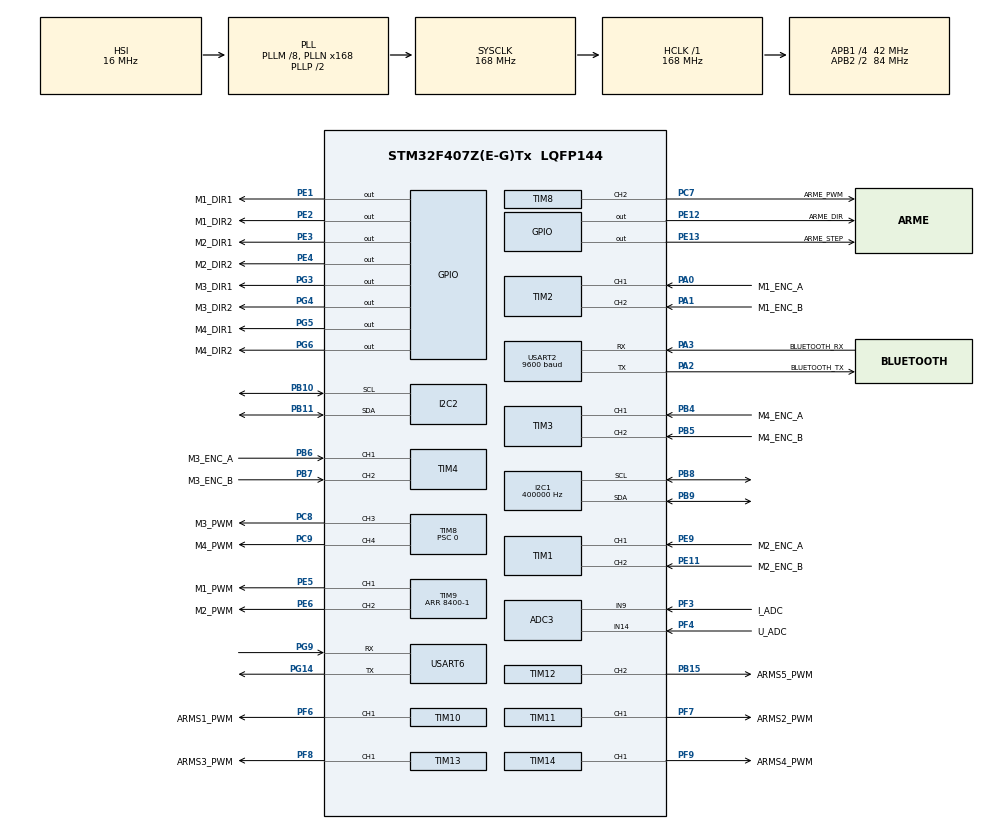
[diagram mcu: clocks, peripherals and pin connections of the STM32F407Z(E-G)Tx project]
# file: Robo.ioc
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ADC3.Channel-5\#ChannelRegularConversion=ADC_CHANNEL_9
ADC3.Channel-6\#ChannelRegularConversion=ADC_CHANNEL_14
ADC3.ClockPrescaler=ADC_CLOCK_SYNC_PCLK_DIV6
ADC3.ContinuousConvMode=ENABLE
ADC3.DMAContinuousRequests=ENABLE
ADC3.NbrOfConversion=2
ADC3.NbrOfConversionFlag=1
ADC3.Rank-5\#ChannelRegularConversion=1
ADC3.Rank-6\#ChannelRegularConversion=2
ADC3.SamplingTime-5\#ChannelRegularConversion=ADC_SAMPLETIME_144CYCLES
ADC3.SamplingTime-6\#ChannelRegularConversion=ADC_SAMPLETIME_144CYCLES
ADC3.ScanConvMode=ENABLE
Dma.ADC3.1.Direction=DMA_PERIPH_TO_MEMORY
Dma.ADC3.1.FIFOMode=DMA_FIFOMODE_DISABLE
Dma.ADC3.1.Instance=DMA2_Stream0
Dma.ADC3.1.MemDataAlignment=DMA_MDATAALIGN_HALFWORD
Dma.ADC3.1.MemInc=DMA_MINC_ENABLE
Dma.ADC3.1.Mode=DMA_CIRCULAR
Dma.ADC3.1.PeriphDataAlignment=DMA_PDATAALIGN_HALFWORD
Dma.ADC3.1.PeriphInc=DMA_PINC_DISABLE
Dma.ADC3.1.Priority=DMA_PRIORITY_HIGH
Dma.Request0=USART2_RX
Dma.Request1=ADC3
Dma.USART2_RX.0.Direction=DMA_PERIPH_TO_MEMORY
Dma.USART2_RX.0.FIFOMode=DMA_FIFOMODE_DISABLE
Dma.USART2_RX.0.Instance=DMA1_Stream5
Dma.USART2_RX.0.MemDataAlignment=DMA_MDATAALIGN_BYTE
Dma.USART2_RX.0.MemInc=DMA_MINC_ENABLE
Dma.USART2_RX.0.Mode=DMA_CIRCULAR
Dma.USART2_RX.0.PeriphDataAlignment=DMA_PDATAALIGN_BYTE
Dma.USART2_RX.0.PeriphInc=DMA_PINC_DISABLE
Dma.USART2_RX.0.Priority=DMA_PRIORITY_VERY_HIGH
FREERTOS.Queues01=remote_chassis,6,uint16_t,0,Static,remote_chassisBuffer,remote_chassisControlBlock
FREERTOS.Tasks01=ChassisTask,47,512,StartChassisTask,As weak,NULL,Dynamic,NULL,NULL;ActuatorTask,13,256,StartActuatorTask,As weak,NULL,Dynamic,NULL,NULL;SafetyTask,41,256,StartSafetyTask,As weak,NULL,Dynamic,NULL,NULL;SensorImuTask,38,512,StartSensorImuTask,As weak,NULL,Dynamic,NULL,NULL;OLEDPowerTask,35,768,StartOLEDPower,As weak,NULL,Dynamic,NULL,NULL;GrabTask,35,512,StartGrabTask,As weak,NULL,Dynamic,NULL,NULL;RemoteTask,32,512,StartRemoteTask,As weak,NULL,Dynamic,NULL,NULL
FREERTOS.configTOTAL_HEAP_SIZE=40960
I2C1.ClockSpeed=400000
I2C1.I2C_Mode=I2C_Fast
I2C2.I2C_Mode=I2C_Fast
IWDG.Prescaler=IWDG_PRESCALER_256
IWDG.Reload=500
Mcu.Family=STM32F4
Mcu.Name=STM32F407Z(E-G)Tx
Mcu.Package=LQFP144
NVIC.DMA1_Stream5_IRQn=true\:5\:0\:false\:false\:true\:true\:false\:true\:true
NVIC.DMA2_Stream0_IRQn=true\:5\:0\:false\:false\:true\:true\:false\:true\:true
NVIC.PriorityGroup=NVIC_PRIORITYGROUP_4
NVIC.TIM5_IRQn=true\:5\:0\:false\:false\:true\:true\:true\:true\:true
NVIC.TIM6_DAC_IRQn=true\:15\:0\:false\:false\:true\:false\:false\:true\:true
NVIC.TimeBase=TIM6_DAC_IRQn
NVIC.TimeBaseIP=TIM6
PA0-WKUP.GPIO_Label=M1_ENC_A
PA0-WKUP.Signal=S_TIM2_CH1_ETR
PA1.GPIO_Label=M1_ENC_B
PA1.Signal=S_TIM2_CH2
PA13.Mode=Serial_Wire
PA13.Signal=SYS_JTMS-SWDIO
PA14.Mode=Serial_Wire
PA14.Signal=SYS_JTCK-SWCLK
PA2.GPIO_Label=BLUETOOTH_TX
PA2.Mode=Asynchronous
PA2.Signal=USART2_TX
PA3.GPIO_Label=BLUETOOTH_RX
PA3.Mode=Asynchronous
PA3.Signal=USART2_RX
PB10.Mode=I2C
PB10.Signal=I2C2_SCL
PB11.Mode=I2C
PB11.Signal=I2C2_SDA
PB15.GPIO_Label=ARMS5_PWM
PB15.Signal=S_TIM12_CH2
PB4.GPIO_Label=M4_ENC_A
PB4.Signal=S_TIM3_CH1
PB5.GPIO_Label=M4_ENC_B
PB5.Signal=S_TIM3_CH2
PB6.GPIO_Label=M3_ENC_A
PB6.Signal=S_TIM4_CH1
PB7.GPIO_Label=M3_ENC_B
PB7.Signal=S_TIM4_CH2
PB8.Mode=I2C
PB8.Signal=I2C1_SCL
PB9.Mode=I2C
PB9.Signal=I2C1_SDA
PC7.GPIO_Label=ARME_PWM
PC7.Signal=S_TIM8_CH2
PC8.GPIO_Label=M3_PWM
PC8.Signal=S_TIM8_CH3
PC9.GPIO_Label=M4_PWM
PC9.Signal=S_TIM8_CH4
PE1.GPIO_Label=M1_DIR1
PE1.Signal=GPIO_Output
PE11.GPIO_Label=M2_ENC_B
PE11.Signal=S_TIM1_CH2
PE12.GPIO_Label=ARME_DIR
PE12.Signal=GPIO_Output
PE13.GPIO_Label=ARME_STEP
PE13.Signal=GPIO_Output
PE2.GPIO_Label=M1_DIR2
PE2.Signal=GPIO_Output
PE3.GPIO_Label=M2_DIR1
PE3.Signal=GPIO_Output
PE4.GPIO_Label=M2_DIR2
PE4.Signal=GPIO_Output
PE5.GPIO_Label=M1_PWM
PE5.Signal=S_TIM9_CH1
PE6.GPIO_Label=M2_PWM
PE6.Signal=S_TIM9_CH2
PE9.GPIO_Label=M2_ENC_A
PE9.Signal=S_TIM1_CH1
PF3.GPIO_Label=I_ADC
PF3.Mode=IN9
PF3.Signal=ADC3_IN9
PF4.GPIO_Label=U_ADC
PF4.Mode=IN14
PF4.Signal=ADC3_IN14
PF6.GPIO_Label=ARMS1_PWM
PF6.Signal=S_TIM10_CH1
PF7.GPIO_Label=ARMS2_PWM
PF7.Signal=S_TIM11_CH1
PF8.GPIO_Label=ARMS3_PWM
PF8.Signal=S_TIM13_CH1
PF9.GPIO_Label=ARMS4_PWM
PF9.Signal=S_TIM14_CH1
PG14.Mode=Asynchronous
PG14.Signal=USART6_TX
PG3.GPIO_Label=M3_DIR1
PG3.Signal=GPIO_Output
PG4.GPIO_Label=M3_DIR2
PG4.Signal=GPIO_Output
PG5.GPIO_Label=M4_DIR1
PG5.Signal=GPIO_Output
PG6.GPIO_Label=M4_DIR2
PG6.Signal=GPIO_Output
PG9.Mode=Asynchronous
PG9.Signal=USART6_RX
PH0-OSC_IN.Mode=HSE-External-Oscillator
PH0-OSC_IN.Signal=RCC_OSC_IN
PH1-OSC_OUT.Mode=HSE-External-Oscillator
PH1-OSC_OUT.Signal=RCC_OSC_OUT
ProjectManager.HeapSize=0x200
ProjectManager.StackSize=0x400
ProjectManager.TargetToolchain=CMake
RCC.48MHZClocksFreq_Value=84000000
RCC.AHBFreq_Value=168000000
RCC.APB1CLKDivider=RCC_HCLK_DIV4
RCC.APB1Freq_Value=42000000
RCC.APB1TimFreq_Value=84000000
RCC.APB2CLKDivider=RCC_HCLK_DIV2
RCC.APB2Freq_Value=84000000
RCC.APB2TimFreq_Value=168000000
RCC.CortexFreq_Value=168000000
RCC.HCLKFreq_Value=168000000
RCC.HSE_VALUE=25000000
RCC.HSI_VALUE=16000000
RCC.LSE_VALUE=32768
RCC.PLLM=8
RCC.PLLN=168
RCC.SYSCLKFreq_VALUE=168000000
RCC.SYSCLKSource=RCC_SYSCLKSOURCE_PLLCLK
RCC.VCOOutputFreq_Value=336000000
SH.S_TIM10_CH1.0=TIM10_CH1,PWM Generation1 CH1
SH.S_TIM11_CH1.0=TIM11_CH1,PWM Generation1 CH1
SH.S_TIM12_CH2.0=TIM12_CH2,PWM Generation2 CH2
SH.S_TIM13_CH1.0=TIM13_CH1,PWM Generation1 CH1
SH.S_TIM14_CH1.0=TIM14_CH1,PWM Generation1 CH1
SH.S_TIM1_CH1.0=TIM1_CH1,Encoder_Interface
SH.S_TIM1_CH2.0=TIM1_CH2,Encoder_Interface
SH.S_TIM2_CH1_ETR.0=TIM2_CH1,Encoder_Interface
SH.S_TIM2_CH2.0=TIM2_CH2,Encoder_Interface
SH.S_TIM3_CH1.0=TIM3_CH1,Encoder_Interface
SH.S_TIM3_CH2.0=TIM3_CH2,Encoder_Interface
SH.S_TIM4_CH1.0=TIM4_CH1,Encoder_Interface
SH.S_TIM4_CH2.0=TIM4_CH2,Encoder_Interface
SH.S_TIM8_CH2.0=TIM8_CH2,PWM Generation2 CH2
SH.S_TIM8_CH3.0=TIM8_CH3,PWM Generation3 CH3
SH.S_TIM8_CH4.0=TIM8_CH4,PWM Generation4 CH4
SH.S_TIM9_CH1.0=TIM9_CH1,PWM Generation1 CH1
SH.S_TIM9_CH2.0=TIM9_CH2,PWM Generation2 CH2
TIM1.EncoderMode=TIM_ENCODERMODE_TI12
TIM1.IC1Filter=8
TIM1.IC2Filter=8
TIM10.AutoReloadPreload=TIM_AUTORELOAD_PRELOAD_ENABLE
TIM10.Channel=TIM_CHANNEL_1
TIM10.Period=20000-1
TIM10.Prescaler=168-1
TIM11.AutoReloadPreload=TIM_AUTORELOAD_PRELOAD_ENABLE
TIM11.Channel=TIM_CHANNEL_1
TIM11.Period=20000-1
TIM11.Prescaler=168-1
TIM12.AutoReloadPreload=TIM_AUTORELOAD_PRELOAD_ENABLE
TIM12.Channel-PWM\ Generation2\ CH2=TIM_CHANNEL_2
TIM12.Period=20000-1
TIM12.Prescaler=84-1
TIM13.AutoReloadPreload=TIM_AUTORELOAD_PRELOAD_ENABLE
TIM13.Channel=TIM_CHANNEL_1
TIM13.Period=20000-1
TIM13.Prescaler=84-1
TIM14.AutoReloadPreload=TIM_AUTORELOAD_PRELOAD_ENABLE
TIM14.Channel=TIM_CHANNEL_1
TIM14.Period=20000-1
TIM14.Prescaler=84-1
TIM2.EncoderMode=TIM_ENCODERMODE_TI12
TIM2.IC1Filter=8
TIM2.IC2Filter=8
TIM3.EncoderMode=TIM_ENCODERMODE_TI12
TIM3.IC1Filter=8
TIM3.IC2Filter=8
TIM4.EncoderMode=TIM_ENCODERMODE_TI12
TIM4.IC1Filter=8
TIM4.IC2Filter=8
TIM5.AutoReloadPreload=TIM_AUTORELOAD_PRELOAD_ENABLE
TIM5.Period=1000-1
TIM5.Prescaler=84-1
TIM8.Channel-PWM\ Generation2\ CH2=TIM_CHANNEL_2
TIM8.Channel-PWM\ Generation3\ CH3=TIM_CHANNEL_3
TIM8.Channel-PWM\ Generation4\ CH4=TIM_CHANNEL_4
TIM8.Period=8400-1
TIM8.Prescaler=0
TIM9.Channel-PWM\ Generation1\ CH1=TIM_CHANNEL_1
TIM9.Channel-PWM\ Generation2\ CH2=TIM_CHANNEL_2
TIM9.Period=8400-1
USART2.BaudRate=9600
USART2.VirtualMode=VM_ASYNC
USART6.VirtualMode=VM_ASYNC
VP_FREERTOS_VS_CMSIS_V2.Mode=CMSIS_V2
VP_IWDG_VS_IWDG.Mode=IWDG_Activate
VP_SYS_VS_tim6.Mode=TIM6
VP_TIM10_VS_ClockSourceINT.Mode=Enable_Timer
VP_TIM11_VS_ClockSourceINT.Mode=Enable_Timer
VP_TIM13_VS_ClockSourceINT.Mode=Enable_Timer
VP_TIM14_VS_ClockSourceINT.Mode=Enable_Timer
VP_TIM5_VS_ClockSourceINT.Mode=Internal
board=custom

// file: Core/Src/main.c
/* USER CODE BEGIN Header */
/**
  ******************************************************************************
  * @file           : main.c
  * @brief          : Main program body
  ******************************************************************************
  * @attention
  *
  * Copyright (c) 2026 STMicroelectronics.
  * All rights reserved.
  *
  * This software is licensed under terms that can be found in the LICENSE file
  * in the root directory of this software component.
  * If no LICENSE file comes with this software, it is provided AS-IS.
  *
  ******************************************************************************
  */
/* USER CODE END Header */
#include "main.h"
#include "cmsis_os.h"
#include "adc.h"
#include "dma.h"
#include "i2c.h"
#include "iwdg.h"
#include "tim.h"
#include "usart.h"
#include "gpio.h"

/* USER CODE BEGIN Includes */
#include "app_types.h" /* App_Init() 与任务入口声明（user/app_types.h）*/
#include "stepper.h"
/* USER CODE END Includes */

void SystemClock_Config(void);
void MX_FREERTOS_Init(void);

int main(void)
{

  /* MCU Configuration--------------------------------------------------------*/

  /* Reset of all peripherals, Initializes the Flash interface and the Systick. */
  HAL_Init();

  /* Configure the system clock */
  SystemClock_Config();

  /* Initialize all configured peripherals */
  MX_GPIO_Init();
  MX_DMA_Init();
  MX_TIM2_Init();
  MX_TIM3_Init();
  MX_TIM4_Init();
  MX_TIM8_Init();
  MX_TIM12_Init();
  MX_ADC3_Init();
  MX_I2C2_Init();
  MX_TIM9_Init();
  MX_USART2_UART_Init();
  MX_USART6_UART_Init();
  MX_TIM10_Init();
  MX_TIM11_Init();
  MX_TIM13_Init();
  MX_TIM14_Init();
  MX_TIM1_Init();
  MX_I2C1_Init();
  MX_IWDG_Init();
  MX_TIM5_Init();
  /* USER CODE BEGIN 2 */

  /* 应用层初始化：建静态队列 + 建任务（全部 xTaskCreateStatic，不用 heap）。
   * 必须在 osKernelStart() 之前调用：任务创建本身不依赖调度器，
   * 但必须在调度器启动时就已经存在于就绪列表里。
   * 详见 user/remote.c 的 App_Init()。 */
  App_Init();

  /* USER CODE END 2 */

  /* Init scheduler */
  osKernelInitialize();  /* Call init function for freertos objects (in cmsis_os2.c) */
  MX_FREERTOS_Init();

  /* Start scheduler */
  osKernelStart();

  /* We should never get here as control is now taken by the scheduler */

  /* Infinite loop */
  while (1)
  {

  }
}

void SystemClock_Config(void)
{
  RCC_OscInitTypeDef RCC_OscInitStruct = {0};
  RCC_ClkInitTypeDef RCC_ClkInitStruct = {0};

  /** Configure the main internal regulator output voltage
  */
  __HAL_RCC_PWR_CLK_ENABLE();
  __HAL_PWR_VOLTAGESCALING_CONFIG(PWR_REGULATOR_VOLTAGE_SCALE1);

  /** Initializes the RCC Oscillators according to the specified parameters
  * in the RCC_OscInitTypeDef structure.
  */
  RCC_OscInitStruct.OscillatorType = RCC_OSCILLATORTYPE_HSI|RCC_OSCILLATORTYPE_LSI;
  RCC_OscInitStruct.HSIState = RCC_HSI_ON;
  RCC_OscInitStruct.HSICalibrationValue = RCC_HSICALIBRATION_DEFAULT;
  RCC_OscInitStruct.LSIState = RCC_LSI_ON;
  RCC_OscInitStruct.PLL.PLLState = RCC_PLL_ON;
  RCC_OscInitStruct.PLL.PLLSource = RCC_PLLSOURCE_HSI;
  RCC_OscInitStruct.PLL.PLLM = 8;
  RCC_OscInitStruct.PLL.PLLN = 168;
  RCC_OscInitStruct.PLL.PLLP = RCC_PLLP_DIV2;
  RCC_OscInitStruct.PLL.PLLQ = 4;
  if (HAL_RCC_OscConfig(&RCC_OscInitStruct) != HAL_OK)
  {
    Error_Handler();
  }

  /** Initializes the CPU, AHB and APB buses clocks
  */
  RCC_ClkInitStruct.ClockType = RCC_CLOCKTYPE_HCLK|RCC_CLOCKTYPE_SYSCLK
                              |RCC_CLOCKTYPE_PCLK1|RCC_CLOCKTYPE_PCLK2;
  RCC_ClkInitStruct.SYSCLKSource = RCC_SYSCLKSOURCE_PLLCLK;
  RCC_ClkInitStruct.AHBCLKDivider = RCC_SYSCLK_DIV1;
  RCC_ClkInitStruct.APB1CLKDivider = RCC_HCLK_DIV4;
  RCC_ClkInitStruct.APB2CLKDivider = RCC_HCLK_DIV2;

  if (HAL_RCC_ClockConfig(&RCC_ClkInitStruct, FLASH_LATENCY_5) != HAL_OK)
  {
    Error_Handler();
  }
}

void HAL_TIM_PeriodElapsedCallback(TIM_HandleTypeDef *htim)
{
  if (htim->Instance == TIM6)
  {
    HAL_IncTick();
  }
  /* USER CODE BEGIN Callback 1 */

  if (htim->Instance == TIM5)
  {
    Stepper_TIM5_PeriodElapsed();
  }

  /* USER CODE END Callback 1 */
}

void Error_Handler(void)
{
  __disable_irq();
  while (1)
  {
  }
}

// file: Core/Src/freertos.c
/* USER CODE BEGIN Header */
/**
  ******************************************************************************
  * File Name          : freertos.c
  * Description        : Code for freertos applications
  ******************************************************************************
  * @attention
  *
  * Copyright (c) 2026 STMicroelectronics.
  * All rights reserved.
  *
  * This software is licensed under terms that can be found in the LICENSE file
  * in the root directory of this software component.
  * If no LICENSE file comes with this software, it is provided AS-IS.
  *
  ******************************************************************************
  */
/* USER CODE END Header */

#include "FreeRTOS.h"
#include "task.h"
#include "main.h"
#include "cmsis_os.h"

typedef StaticQueue_t osStaticMessageQDef_t;

/* Definitions for ChassisTask */
osThreadId_t ChassisTaskHandle;
const osThreadAttr_t ChassisTask_attributes = {
  .name = "ChassisTask",
  .stack_size = 512 * 4,
  .priority = (osPriority_t) osPriorityHigh7,
};
/* Definitions for ActuatorTask */
osThreadId_t ActuatorTaskHandle;
const osThreadAttr_t ActuatorTask_attributes = {
  .name = "ActuatorTask",
  .stack_size = 256 * 4,
  .priority = (osPriority_t) osPriorityLow5,
};
/* Definitions for SafetyTask */
osThreadId_t SafetyTaskHandle;
const osThreadAttr_t SafetyTask_attributes = {
  .name = "SafetyTask",
  .stack_size = 256 * 4,
  .priority = (osPriority_t) osPriorityHigh1,
};
/* Definitions for SensorImuTask */
osThreadId_t SensorImuTaskHandle;
const osThreadAttr_t SensorImuTask_attributes = {
  .name = "SensorImuTask",
  .stack_size = 512 * 4,
  .priority = (osPriority_t) osPriorityAboveNormal6,
};
/* Definitions for OLEDPowerTask */
osThreadId_t OLEDPowerTaskHandle;
const osThreadAttr_t OLEDPowerTask_attributes = {
  .name = "OLEDPowerTask",
  .stack_size = 768 * 4,
  .priority = (osPriority_t) osPriorityAboveNormal3,
};
/* Definitions for GrabTask */
osThreadId_t GrabTaskHandle;
const osThreadAttr_t GrabTask_attributes = {
  .name = "GrabTask",
  .stack_size = 512 * 4,
  .priority = (osPriority_t) osPriorityAboveNormal3,
};
/* Definitions for RemoteTask */
osThreadId_t RemoteTaskHandle;
const osThreadAttr_t RemoteTask_attributes = {
  .name = "RemoteTask",
  .stack_size = 512 * 4,
  .priority = (osPriority_t) osPriorityAboveNormal,
};
/* Definitions for remote_chassis */
osMessageQueueId_t remote_chassisHandle;
uint8_t remote_chassisBuffer[ 6 * sizeof( uint16_t ) ];
osStaticMessageQDef_t remote_chassisControlBlock;
const osMessageQueueAttr_t remote_chassis_attributes = {
  .name = "remote_chassis",
  .cb_mem = &remote_chassisControlBlock,
  .cb_size = sizeof(remote_chassisControlBlock),
  .mq_mem = &remote_chassisBuffer,
  .mq_size = sizeof(remote_chassisBuffer)
};

void StartChassisTask(void *argument);
void StartActuatorTask(void *argument);
void StartSafetyTask(void *argument);
void StartSensorImuTask(void *argument);
void StartOLEDPower(void *argument);
void StartGrabTask(void *argument);
void StartRemoteTask(void *argument);

void MX_FREERTOS_Init(void); /* (MISRA C 2004 rule 8.1) */

void MX_FREERTOS_Init(void) {

  /* Create the queue(s) */
  /* creation of remote_chassis */
  remote_chassisHandle = osMessageQueueNew (6, sizeof(uint16_t), &remote_chassis_attributes);

  /* Create the thread(s) */
  /* creation of ChassisTask */
  ChassisTaskHandle = osThreadNew(StartChassisTask, NULL, &ChassisTask_attributes);

  /* creation of ActuatorTask */
  ActuatorTaskHandle = osThreadNew(StartActuatorTask, NULL, &ActuatorTask_attributes);

  /* creation of SafetyTask */
  SafetyTaskHandle = osThreadNew(StartSafetyTask, NULL, &SafetyTask_attributes);

  /* creation of SensorImuTask */
  SensorImuTaskHandle = osThreadNew(StartSensorImuTask, NULL, &SensorImuTask_attributes);

  /* creation of OLEDPowerTask */
  OLEDPowerTaskHandle = osThreadNew(StartOLEDPower, NULL, &OLEDPowerTask_attributes);

  /* creation of GrabTask */
  GrabTaskHandle = osThreadNew(StartGrabTask, NULL, &GrabTask_attributes);

  /* creation of RemoteTask */
  RemoteTaskHandle = osThreadNew(StartRemoteTask, NULL, &RemoteTask_attributes);

}

__weak void StartChassisTask(void *argument)
{
  for(;;)
  {
    osDelay(1);
  }
}

__weak void StartActuatorTask(void *argument)
{
  for(;;)
  {
    osDelay(1);
  }
}

__weak void StartSafetyTask(void *argument)
{
  for(;;)
  {
    osDelay(1);
  }
}

__weak void StartSensorImuTask(void *argument)
{
  for(;;)
  {
    osDelay(1);
  }
}

__weak void StartOLEDPower(void *argument)
{
  for(;;)
  {
    osDelay(1);
  }
}

__weak void StartGrabTask(void *argument)
{
  for(;;)
  {
    osDelay(1);
  }
}

__weak void StartRemoteTask(void *argument)
{
  for(;;)
  {
    osDelay(1);
  }
}
